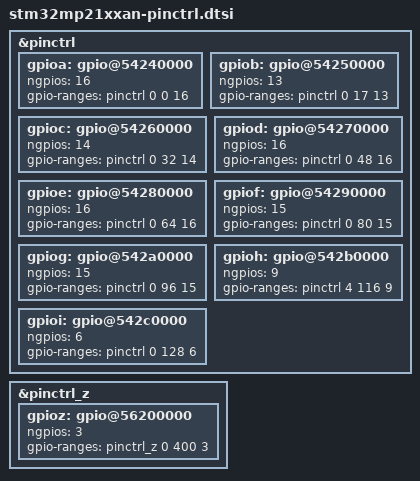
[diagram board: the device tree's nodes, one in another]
/*
 * Copyright (c) 2026, STMicroelectronics - All Rights Reserved
 *
 * SPDX-License-Identifier: Apache-2.0
 */

&pinctrl {
	#gpio-range-cells = <3>;

	gpioa: gpio@54240000 {
		status = "okay";
		ngpios = <16>;
		gpio-ranges = <&pinctrl 0 0 16>;
	};

	gpiob: gpio@54250000 {
		status = "okay";
		ngpios = <13>;
		gpio-ranges = <&pinctrl 0 17 13>;
	};

	gpioc: gpio@54260000 {
		status = "okay";
		ngpios = <14>;
		gpio-ranges = <&pinctrl 0 32 14>;
	};

	gpiod: gpio@54270000 {
		status = "okay";
		ngpios = <16>;
		gpio-ranges = <&pinctrl 0 48 16>;
	};

	gpioe: gpio@54280000 {
		status = "okay";
		ngpios = <16>;
		gpio-ranges = <&pinctrl 0 64 16>;
	};

	gpiof: gpio@54290000 {
		status = "okay";
		ngpios = <15>;
		gpio-ranges = <&pinctrl 0 80 15>;
	};

	gpiog: gpio@542a0000 {
		status = "okay";
		ngpios = <15>;
		gpio-ranges = <&pinctrl 0 96 15>;
	};

	gpioh: gpio@542b0000 {
		status = "okay";
		ngpios = <9>;
		gpio-ranges = <&pinctrl 4 116 9>;
	};

	gpioi: gpio@542c0000 {
		status = "okay";
		ngpios = <6>;
		gpio-ranges = <&pinctrl 0 128 6>;
	};
};

&pinctrl_z {
	gpioz: gpio@56200000 {
		status = "okay";
		ngpios = <3>;
		gpio-ranges = <&pinctrl_z 0 400 3>;
	};
};

